# STM32H7x5 register map
File version: 1.1
CPU: CM7 r0p0, little endian, no MPU, no FPU, 3 interrupt priority bits
Registers are 32-bit, read-write, reset 0x0 unless marked. A register's access mark holds for its fields unless they carry their own. Offsets are from the block's base; [hi:lo] are bit positions; {n}, {i} and the like mark numbered series; 'fields as' and 'values as' point back to an identical list.

## FMC
Base 0x52004000
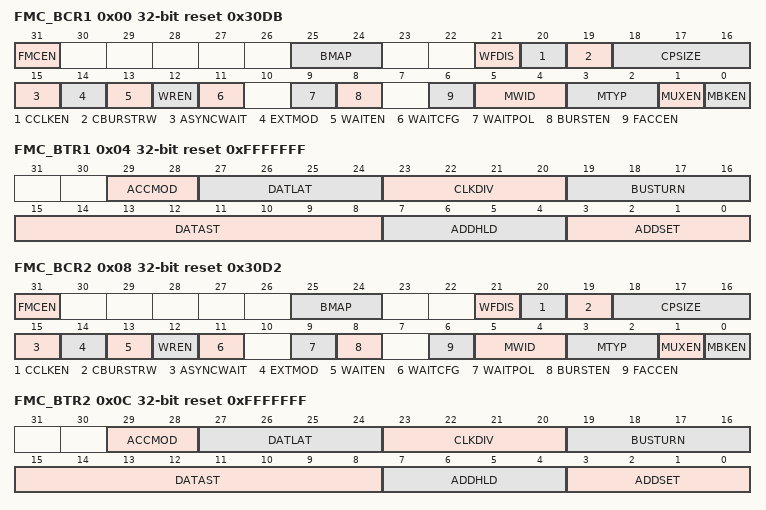
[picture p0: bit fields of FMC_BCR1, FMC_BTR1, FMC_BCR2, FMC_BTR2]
0x00 FMC_BCR1 reset 0x30DB — This register contains the control information of each memory bank, used for SRAMs, PSRAM and NOR Flash memories.
  [31] FMCEN — FMC controller Enable This bit enables/disables the FMC controller. Note: The FMCEN bit of the FMC_BCR2..4 registers is dont care. It is only enabled through the FMC_BCR1 register.
  [25:24] BMAP — FMC bank mapping These bits allows different to remap SDRAM bank2 or swap the FMC NOR/PSRAM and SDRAM banks.Refer to Table 10 for Note: The BMAP bits of the FMC_BCR2..4 registers are dont care. It is only enabled through the FMC_BCR1 register.
  [21] WFDIS — Write FIFO Disable This bit disables the Write FIFO used by the FMC controller. Note: The WFDIS bit of the FMC_BCR2..4 registers is dont care. It is only enabled through the FMC_BCR1 register.
  [20] CCLKEN — Continuous Clock Enable This bit enables the FMC_CLK clock output to external memory devices. Note: The CCLKEN bit of the FMC_BCR2..4 registers is dont care. It is only enabled through the FMC_BCR1 register. Bank 1 must be configured in synchronous mode to generate the FMC_CLK continuous clock. If CCLKEN bit is set, the FMC_CLK clock ratio is specified by CLKDIV value in the FMC_BTR1 register. CLKDIV in FMC_BWTR1 is dont care. If the synchronous mode is used and CCLKEN bit is set, the synchronous memories connected to other banks than Bank 1 are clocked by the same clock (the CLKDIV value in the FMC_BTR2..4 and FMC_BWTR2..4 registers for other banks has no effect.)
  [19] CBURSTRW — Write burst enable For PSRAM (CRAM) operating in Burst mode, the bit enables synchronous accesses during write operations. The enable bit for synchronous read accesses is the BURSTEN bit in the FMC_BCRx register.
  [18:16] CPSIZE — CRAM Page Size These are used for Cellular RAM 1.5 which does not allow burst access to cross the address boundaries between pages. When these bits are configured, the FMC controller splits automatically the burst access when the memory page size is reached (refer to memory datasheet for page size). Other configuration: reserved.
  [15] ASYNCWAIT — Wait signal during asynchronous transfers This bit enables/disables the FMC to use the wait signal even during an asynchronous protocol.
  [14] EXTMOD — Extended mode enable. This bit enables the FMC to program the write timings for asynchronous accesses inside the FMC_BWTR register, thus resulting in different timings for read and write operations. Note: When the extended mode is disabled, the FMC can operate in Mode1 or Mode2 as follows: ** Mode 1 is the default mode when the SRAM/PSRAM memory type is selected (MTYP =0x0 or 0x01) ** Mode 2 is the default mode when the NOR memory type is selected (MTYP = 0x10).
  [13] WAITEN — Wait enable bit This bit enables/disables wait-state insertion via the NWAIT signal when accessing the memory in synchronous mode.
  [12] WREN — Write enable bit This bit indicates whether write operations are enabled/disabled in the bank by the FMC:
  [11] WAITCFG — Wait timing configuration The NWAIT signal indicates whether the data from the memory are valid or if a wait state must be inserted when accessing the memory in synchronous mode. This configuration bit determines if NWAIT is asserted by the memory one clock cycle before the wait state or during the wait state:
  [9] WAITPOL — Wait signal polarity bit This bit defines the polarity of the wait signal from memory used for either in synchronous or asynchronous mode:
  [8] BURSTEN — Burst enable bit This bit enables/disables synchronous accesses during read operations. It is valid only for synchronous memories operating in Burst mode:
  [6] FACCEN — Flash access enable This bit enables NOR Flash memory access operations.
  [5:4] MWID — Memory data bus width Defines the external memory device width, valid for all type of memories.
  [3:2] MTYP — Memory type These bits define the type of external memory attached to the corresponding memory bank:
  [1] MUXEN — Address/data multiplexing enable bit When this bit is set, the address and data values are multiplexed on the data bus, valid only with NOR and PSRAM memories:
  [0] MBKEN — Memory bank enable bit This bit enables the memory bank. After reset Bank1 is enabled, all others are disabled. Accessing a disabled bank causes an ERROR on AXI bus.
0x04 FMC_BTR1 reset 0xFFFFFFF — This register contains the control information of each memory bank, used for SRAMs, PSRAM and NOR Flash memories.If the EXTMOD bit is set in the FMC_BCRx register, then this register is partitioned for write and read access, that is, 2 registers are available: one to configure read accesses (this register) and one to configure write accesses (FMC_BWTRx registers).
  [29:28] ACCMOD — Access mode These bits specify the asynchronous access modes as shown in the timing diagrams. They are taken into account only when the EXTMOD bit in the FMC_BCRx register is 1.
  [27:24] DATLAT — Data latency for synchronous memory For synchronous access with read write burst mode enabled these bits define the number of memory clock cycles
  [23:20] CLKDIV — Clock divide ratio (for FMC_CLK signal) These bits define the period of FMC_CLK clock output signal, expressed in number of KCK_FMC cycles: In asynchronous NOR Flash, SRAM or PSRAM accesses, this value is dont care. Note: Refer to Section20.6.5: Synchronous transactions for FMC_CLK divider ratio formula)
  [19:16] BUSTURN — Bus turnaround phase duration These bits are written by software to add a delay at the end of a write-to-read or read-to write transaction. The programmed bus turnaround delay is inserted between an asynchronous read (in muxed or mode D) or write transaction and any other asynchronous /synchronous read/write from/to a static bank. If a read operation is performed, the bank can be the same or a different one, whereas it must be different in case of write operation to the bank, except in muxed mode or mode D. In some cases, whatever the programmed BUSTRUN values, the bus turnaround delay is fixed as follows: The bus turnaround delay is not inserted between two consecutive asynchronous write transfers to the same static memory bank except in muxed mode and mode D. There is a bus turnaround delay of 1 FMC clock cycle between: Two consecutive asynchronous read transfers to the same static memory bank except for modes muxed and D. An asynchronous read to an asynchronous or synchronous write to any static bank or dynamic bank except in modes muxed and D mode. There is a bus turnaround delay of 2 FMC clock cycle between: Two consecutive synchronous write operations (in Burst or Single mode) to the same bank. A synchronous write (burst or single) access and an asynchronous write or read transfer to or from static memory bank (the bank can be the same or a different one in case of a read operation. Two consecutive synchronous read operations (in Burst or Single mode) followed by any synchronous/asynchronous read or write from/to another static memory bank. There is a bus turnaround delay of 3 FMC clock cycle between: Two consecutive synchronous write operations (in Burst or Single mode) to different static banks. A synchronous write access (in Burst or Single mode) and a synchronous read from the same or a different bank. The bus turnaround delay allows to match the minimum time between consecutive transactions (tEHEL from NEx high to NEx low) and the maximum time required by the memory to free the data bus after a read access (tEHQZ): (BUSTRUN + 1) KCK_FMC period ≥ tEHELmin and (BUSTRUN + 2)KCK_FMC period ≥ tEHQZmax if EXTMOD = 0 (BUSTRUN + 2)KCK_FMC period ≥ max (tEHELmin, tEHQZmax) if EXTMOD = 126. ...
  [15:8] DATAST — Data-phase duration These bits are written by software to define the duration of the data phase (refer to Figure81 to Figure93), used in asynchronous accesses: For each memory type and access mode data-phase duration, please refer to the respective figure (Figure81 to Figure93). Example: Mode1, write access, DATAST=1: Data-phase duration= DATAST+1 = 2 KCK_FMC clock cycles. Note: In synchronous accesses, this value is dont care.
  [7:4] ADDHLD — Address-hold phase duration These bits are written by software to define the duration of the address hold phase (refer to Figure81 to Figure93), used in mode D or multiplexed accesses: For each access mode address-hold phase duration, please refer to the respective figure (Figure81 to Figure93). Note: In synchronous accesses, this value is not used, the address hold phase is always 1 memory clock period duration.
  [3:0] ADDSET — Address setup phase duration These bits are written by software to define the duration of the address setup phase (refer to Figure81 to Figure93), used in SRAMs, ROMs and asynchronous NOR Flash: For each access mode address setup phase duration, please refer to the respective figure (refer to Figure81 to Figure93). Note: In synchronous accesses, this value is dont care. In Muxed mode or Mode D, the minimum value for ADDSET is 1.
0x08 FMC_BCR2 reset 0x30D2 — This register contains the control information of each memory bank, used for SRAMs, PSRAM and NOR Flash memories.
  fields as FMC_BCR1
0x0C FMC_BTR2 reset 0xFFFFFFF — This register contains the control information of each memory bank, used for SRAMs, PSRAM and NOR Flash memories.If the EXTMOD bit is set in the FMC_BCRx register, then this register is partitioned for write and read access, that is, 2 registers are available: one to configure read accesses (this register) and one to configure write accesses (FMC_BWTRx registers).
  [29:28] ACCMOD — Access mode These bits specify the asynchronous access modes as shown in the timing diagrams. They are taken into account only when the EXTMOD bit in the FMC_BCRx register is 1.
  [27:24] DATLAT — Data latency for synchronous memory For synchronous access with read write burst mode enabled these bits define the number of memory clock cycles
  [23:20] CLKDIV — Clock divide ratio (for FMC_CLK signal) These bits define the period of FMC_CLK clock output signal, expressed in number of KCK_FMC cycles: In asynchronous NOR Flash, SRAM or PSRAM accesses, this value is dont care. Note: Refer to Section20.6.5: Synchronous transactions for FMC_CLK divider ratio formula)
  [19:16] BUSTURN — Bus turnaround phase duration These bits are written by software to add a delay at the end of a write-to-read or read-to write transaction. The programmed bus turnaround delay is inserted between an asynchronous read (in muxed or mode D) or write transaction and any other asynchronous /synchronous read/write from/to a static bank. If a read operation is performed, the bank can be the same or a different one, whereas it must be different in case of write operation to the bank, except in muxed mode or mode D. In some cases, whatever the programmed BUSTRUN values, the bus turnaround delay is fixed as follows: The bus turnaround delay is not inserted between two consecutive asynchronous write transfers to the same static memory bank except in muxed mode and mode D. There is a bus turnaround delay of 1 FMC clock cycle between: Two consecutive asynchronous read transfers to the same static memory bank except for modes muxed and D. An asynchronous read to an asynchronous or synchronous write to any static bank or dynamic bank except in modes muxed and D mode. There is a bus turnaround delay of 2 FMC clock cycle between: Two consecutive synchronous write operations (in Burst or Single mode) to the same bank. A synchronous write (burst or single) access and an asynchronous write or read transfer to or from static memory bank (the bank can be the same or a different one in case of a read operation. Two consecutive synchronous read operations (in Burst or Single mode) followed by any synchronous/asynchronous read or write from/to another static memory bank. There is a bus turnaround delay of 3 FMC clock cycle between: Two consecutive synchronous write operations (in Burst or Single mode) to different static banks. A synchronous write access (in Burst or Single mode) and a synchronous read from the same or a different bank. The bus turnaround delay allows to match the minimum time between consecutive transactions (tEHEL from NEx high to NEx low) and the maximum time required by the memory to free the data bus after a read access (tEHQZ): (BUSTRUN + 1) KCK_FMC period ≥ tEHELmin and (BUSTRUN + 2)KCK_FMC period ≥ tEHQZmax if EXTMOD = 0 (BUSTRUN + 2)KCK_FMC period ≥ max (tEHELmin, tEHQZmax) if EXTMOD = 1. ...
  [15:8] DATAST — Data-phase duration These bits are written by software to define the duration of the data phase (refer to Figure81 to Figure93), used in asynchronous accesses: For each memory type and access mode data-phase duration, please refer to the respective figure (Figure81 to Figure93). Example: Mode1, write access, DATAST=1: Data-phase duration= DATAST+1 = 2 KCK_FMC clock cycles. Note: In synchronous accesses, this value is dont care.
  [7:4] ADDHLD — Address-hold phase duration These bits are written by software to define the duration of the address hold phase (refer to Figure81 to Figure93), used in mode D or multiplexed accesses: For each access mode address-hold phase duration, please refer to the respective figure (Figure81 to Figure93). Note: In synchronous accesses, this value is not used, the address hold phase is always 1 memory clock period duration.
  [3:0] ADDSET — Address setup phase duration These bits are written by software to define the duration of the address setup phase (refer to Figure81 to Figure93), used in SRAMs, ROMs and asynchronous NOR Flash: For each access mode address setup phase duration, please refer to the respective figure (refer to Figure81 to Figure93). Note: In synchronous accesses, this value is dont care. In Muxed mode or Mode D, the minimum value for ADDSET is 1.
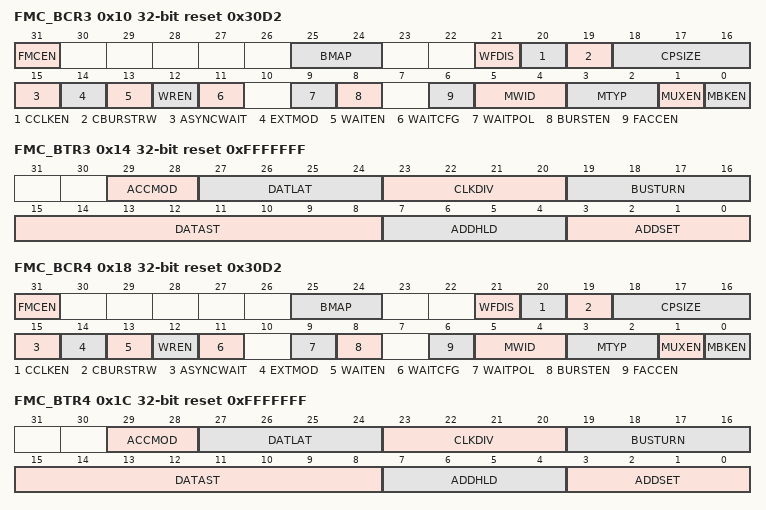
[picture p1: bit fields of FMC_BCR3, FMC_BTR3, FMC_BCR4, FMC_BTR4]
0x10 FMC_BCR3 reset 0x30D2 — This register contains the control information of each memory bank, used for SRAMs, PSRAM and NOR Flash memories.
  fields as FMC_BCR1
0x14 FMC_BTR3 reset 0xFFFFFFF — This register contains the control information of each memory bank, used for SRAMs, PSRAM and NOR Flash memories.If the EXTMOD bit is set in the FMC_BCRx register, then this register is partitioned for write and read access, that is, 2 registers are available: one to configure read accesses (this register) and one to configure write accesses (FMC_BWTRx registers).
  [29:28] ACCMOD — Access mode These bits specify the asynchronous access modes as shown in the timing diagrams. They are taken into account only when the EXTMOD bit in the FMC_BCRx register is 1.
  [27:24] DATLAT — Data latency for synchronous memory For synchronous access with read write burst mode enabled these bits define the number of memory clock cycles
  [23:20] CLKDIV — Clock divide ratio (for FMC_CLK signal) These bits define the period of FMC_CLK clock output signal, expressed in number of KCK_FMC cycles: In asynchronous NOR Flash, SRAM or PSRAM accesses, this value is dont care. Note: Refer to Section20.6.5: Synchronous transactions for FMC_CLK divider ratio formula)
  [19:16] BUSTURN — Bus turnaround phase duration These bits are written by software to add a delay at the end of a write-to-read or read-to write transaction. The programmed bus turnaround delay is inserted between an asynchronous read (in muxed or mode D) or write transaction and any other asynchronous /synchronous read/write from/to a static bank. If a read operation is performed, the bank can be the same or a different one, whereas it must be different in case of write operation to the bank, except in muxed mode or mode D. In some cases, whatever the programmed BUSTRUN values, the bus turnaround delay is fixed as follows: The bus turnaround delay is not inserted between two consecutive asynchronous write transfers to the same static memory bank except in muxed mode and mode D. There is a bus turnaround delay of 1 FMC clock cycle between: Two consecutive asynchronous read transfers to the same static memory bank except for modes muxed and D. An asynchronous read to an asynchronous or synchronous write to any static bank or dynamic bank except in modes muxed and D mode. There is a bus turnaround delay of 2 FMC clock cycle between: Two consecutive synchronous write operations (in Burst or Single mode) to the same bank. A synchronous write (burst or single) access and an asynchronous write or read transfer to or from static memory bank (the bank can be the same or a different one in case of a read operation. Two consecutive synchronous read operations (in Burst or Single mode) followed by any synchronous/asynchronous read or write from/to another static memory bank. There is a bus turnaround delay of 3 FMC clock cycle between: Two consecutive synchronous write operations (in Burst or Single mode) to different static banks. A synchronous write access (in Burst or Single mode) and a synchronous read from the same or a different bank. The bus turnaround delay allows to match the minimum time between consecutive transactions (tEHEL from NEx high to NEx low) and the maximum time required by the memory to free the data bus after a read access (tEHQZ): (BUSTRUN + 1) KCK_FMC period ≥ tEHELmin and (BUSTRUN + 2)KCK_FMC period ≥ tEHQZmax if EXTMOD = 0 (BUSTRUN + 2)KCK_FMC period ≥ max (tEHELmin, tEHQZmax) if EXTMOD =1. ...
  [15:8] DATAST — Data-phase duration These bits are written by software to define the duration of the data phase (refer to Figure81 to Figure93), used in asynchronous accesses: For each memory type and access mode data-phase duration, please refer to the respective figure (Figure81 to Figure93). Example: Mode1, write access, DATAST=1: Data-phase duration= DATAST+1 = 2 KCK_FMC clock cycles. Note: In synchronous accesses, this value is dont care.
  [7:4] ADDHLD — Address-hold phase duration These bits are written by software to define the duration of the address hold phase (refer to Figure81 to Figure93), used in mode D or multiplexed accesses: For each access mode address-hold phase duration, please refer to the respective figure (Figure81 to Figure93). Note: In synchronous accesses, this value is not used, the address hold phase is always 1 memory clock period duration.
  [3:0] ADDSET — Address setup phase duration These bits are written by software to define the duration of the address setup phase (refer to Figure81 to Figure93), used in SRAMs, ROMs and asynchronous NOR Flash: For each access mode address setup phase duration, please refer to the respective figure (refer to Figure81 to Figure93). Note: In synchronous accesses, this value is dont care. In Muxed mode or Mode D, the minimum value for ADDSET is 1.
0x18 FMC_BCR4 reset 0x30D2 — This register contains the control information of each memory bank, used for SRAMs, PSRAM and NOR Flash memories.
  fields as FMC_BCR1
0x1C FMC_BTR4 reset 0xFFFFFFF — This register contains the control information of each memory bank, used for SRAMs, PSRAM and NOR Flash memories.If the EXTMOD bit is set in the FMC_BCRx register, then this register is partitioned for write and read access, that is, 2 registers are available: one to configure read accesses (this register) and one to configure write accesses (FMC_BWTRx registers).
  fields as FMC_BTR3
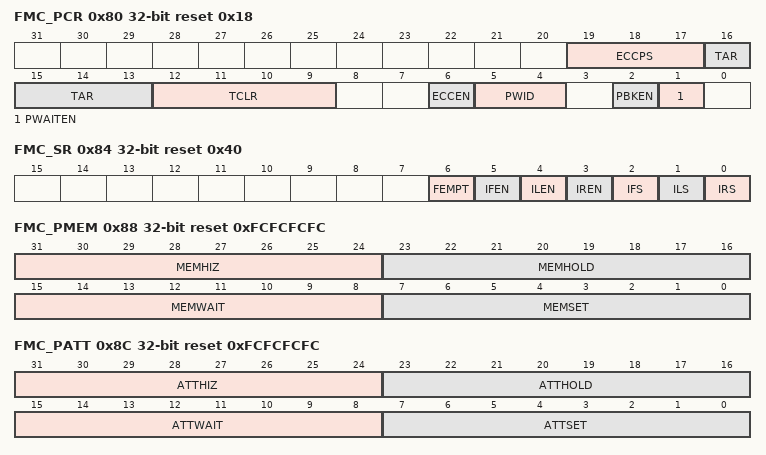
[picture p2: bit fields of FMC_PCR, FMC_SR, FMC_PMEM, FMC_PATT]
0x80 FMC_PCR reset 0x18 — NAND Flash control registers
  [19:17] ECCPS — ECC page size. These bits define the page size for the extended ECC:
  [16:13] TAR — ALE to RE delay. These bits set time from ALE low to RE low in number of KCK_FMC clock cycles. Time is: t_ar = (TAR + SET + 2) TKCK_FMC where TKCK_FMC is the FMC clock period Note: Set is MEMSET or ATTSET according to the addressed space.
  [12:9] TCLR — CLE to RE delay. These bits set time from CLE low to RE low in number of KCK_FMC clock cycles. The time is give by the following formula: t_clr = (TCLR + SET + 2) TKCK_FMC where TKCK_FMC is the KCK_FMC clock period Note: Set is MEMSET or ATTSET according to the addressed space.
  [6] ECCEN — ECC computation logic enable bit
  [5:4] PWID — Data bus width. These bits define the external memory device width.
  [2] PBKEN — NAND Flash memory bank enable bit. This bit enables the memory bank. Accessing a disabled memory bank causes an ERROR on AXI bus
  [1] PWAITEN — Wait feature enable bit. This bit enables the Wait feature for the NAND Flash memory bank:
0x84 FMC_SR access per field reset 0x40 — This register contains information about the FIFO status and interrupt. The FMC features a FIFO that is used when writing to memories to transfer up to 16 words of data.This is used to quickly write to the FIFO and free the AXI bus for transactions to peripherals other than the FMC, while the FMC is draining its FIFO into the memory. One of these register bits indicates the status of the FIFO, for ECC purposes.The ECC is calculated while the data are written to the memory. To read the correct ECC, the software must consequently wait until the FIFO is empty.
  [6] FEMPT ro — FIFO empty. Read-only bit that provides the status of the FIFO
  [5] IFEN rw — Interrupt falling edge detection enable bit
  [4] ILEN rw — Interrupt high-level detection enable bit
  [3] IREN rw — Interrupt rising edge detection enable bit
  [2] IFS rw — Interrupt falling edge status The flag is set by hardware and reset by software. Note: If this bit is written by software to 1 it will be set.
  [1] ILS rw — Interrupt high-level status The flag is set by hardware and reset by software.
  [0] IRS rw — Interrupt rising edge status The flag is set by hardware and reset by software. Note: If this bit is written by software to 1 it will be set.
0x88 FMC_PMEM reset 0xFCFCFCFC — The FMC_PMEM read/write register contains the timing information for NAND Flash memory bank. This information is used to access either the common memory space of the NAND Flash for command, address write access and data read/write access.
  [31:24] MEMHIZ — Common memory x data bus Hi-Z time These bits define the number of KCK_FMC clock cycles during which the data bus is kept Hi-Z after the start of a NAND Flash write access to common memory space. This is only valid for write transactions:
  [23:16] MEMHOLD — Common memory hold time These bits define the number of KCK_FMC clock cycles for write accesses and KCK_FMC+1 clock cycles for read accesses during which the address is held (and data for write accesses) after the command is de-asserted (NWE, NOE), for NAND Flash read or write access to common memory space:
  [15:8] MEMWAIT — Common memory wait time These bits define the minimum number of KCK_FMC (+1) clock cycles to assert the command (NWE, NOE), for NAND Flash read or write access to common memory space. The duration of command assertion is extended if the wait signal (NWAIT) is active (low) at the end of the programmed value of KCK_FMC:
  [7:0] MEMSET — Common memory x setup time These bits define the number of KCK_FMC (+1) clock cycles to set up the address before the command assertion (NWE, NOE), for NAND Flash read or write access to common memory space:
0x8C FMC_PATT reset 0xFCFCFCFC — The FMC_PATT read/write register contains the timing information for NAND Flash memory bank. It is used for 8-bit accesses to the attribute memory space of the NAND Flash for the last address write access if the timing must differ from that of previous accesses (for Ready/Busy management, refer to Section20.8.5: NAND Flash prewait feature).
  [31:24] ATTHIZ — Attribute memory data bus Hi-Z time These bits define the number of KCK_FMC clock cycles during which the data bus is kept in Hi-Z after the start of a NAND Flash write access to attribute memory space on socket. Only valid for writ transaction:
  [23:16] ATTHOLD — Attribute memory hold time These bits define the number of KCK_FMC clock cycles during which the address is held (and data for write access) after the command de-assertion (NWE, NOE), for NAND Flash read or write access to attribute memory space:
  [15:8] ATTWAIT — Attribute memory wait time These bits define the minimum number of x KCK_FMC (+1) clock cycles to assert the command (NWE, NOE), for NAND Flash read or write access to attribute memory space. The duration for command assertion is extended if the wait signal (NWAIT) is active (low) at the end of the programmed value of KCK_FMC:
  [7:0] ATTSET — Attribute memory setup time These bits define the number of KCK_FMC (+1) clock cycles to set up address before the command assertion (NWE, NOE), for NAND Flash read or write access to attribute memory space:
0x94 FMC_ECCR ro — This register contain the current error correction code value computed by the ECC computation modules of the FMC NAND controller. When the CPU reads/writes the data from a NAND Flash memory page at the correct address (refer to Section20.8.6: Computation of the error correction code (ECC) in NAND Flash memory), the data read/written from/to the NAND Flash memory are processed automatically by the ECC computation module. When X bytes have been read (according to the ECCPS field in the FMC_PCR registers), the CPU must read the computed ECC value from the FMC_ECC registers. It then verifies if these computed parity data are the same as the parity value recorded in the spare area, to determine whether a page is valid, and, to correct it otherwise. The FMC_ECCR register should be cleared after being read by setting the ECCEN bit to 0. To compute a new data block, the ECCEN bit must be set to 1.
  [31:0] ECC — ECC result This field contains the value computed by the ECC computation logic. Table167 describes the contents of these bit fields.
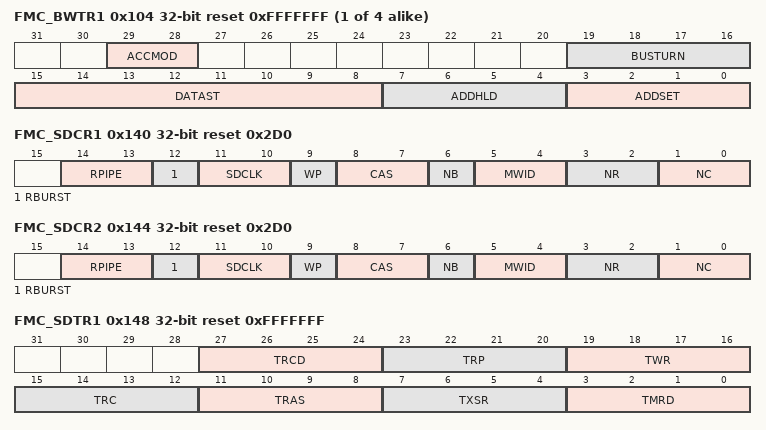
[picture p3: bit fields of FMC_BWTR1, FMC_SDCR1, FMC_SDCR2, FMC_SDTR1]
{0xFC+8i} FMC_BWTR{i} reset 0xFFFFFFF (i=1..4) — This register contains the control information of each memory bank. It is used for SRAMs, PSRAMs and NOR Flash memories. When the EXTMOD bit is set in the FMC_BCRx register, then this register is active for write access.
  [29:28] ACCMOD — Access mode. These bits specify the asynchronous access modes as shown in the next timing diagrams.These bits are taken into account only when the EXTMOD bit in the FMC_BCRx register is 1.
  [19:16] BUSTURN — Bus turnaround phase duration These bits are written by software to add a delay at the end of a write transaction to match the minimum time between consecutive transactions (tEHEL from ENx high to ENx low): (BUSTRUN + 1) KCK_FMC period ≥ tEHELmin. The programmed bus turnaround delay is inserted between a an asynchronous write transfer and any other asynchronous /synchronous read or write transfer to or from a static bank. If a read operation is performed, the bank can be the same or a different one, whereas it must be different in case of write operation to the bank, except in muxed mode or mode D. In some cases, whatever the programmed BUSTRUN values, the bus turnaround delay is fixed as follows: The bus turnaround delay is not inserted between two consecutive asynchronous write transfers to the same static memory bank except for muxed mode and mode D. There is a bus turnaround delay of 2 FMC clock cycle between: Two consecutive synchronous write operations (in Burst or Single mode) to the same bank A synchronous write transfer ((in Burst or Single mode) and an asynchronous write or read transfer to or from static memory bank. There is a bus turnaround delay of 3 FMC clock cycle between: Two consecutive synchronous write operations (in Burst or Single mode) to different static banks. A synchronous write transfer (in Burst or Single mode) and a synchronous read from the same or a different bank. ...
  [15:8] DATAST — Data-phase duration. These bits are written by software to define the duration of the data phase (refer to Figure81 to Figure93), used in asynchronous SRAM, PSRAM and NOR Flash memory accesses:
  [7:4] ADDHLD — Address-hold phase duration. These bits are written by software to define the duration of the address hold phase (refer to Figure81 to Figure93), used in asynchronous multiplexed accesses: ... Note: In synchronous NOR Flash accesses, this value is not used, the address hold phase is always 1 Flash clock period duration.
  [3:0] ADDSET — Address setup phase duration. These bits are written by software to define the duration of the address setup phase in KCK_FMC cycles (refer to Figure81 to Figure93), used in asynchronous accesses: ... Note: In synchronous accesses, this value is not used, the address setup phase is always 1 Flash clock period duration. In muxed mode, the minimum ADDSET value is 1.
0x140 FMC_SDCR1 reset 0x2D0 — This register contains the control parameters for each SDRAM memory bank
  [14:13] RPIPE — Read pipe These bits define the delay, in KCK_FMC clock cycles, for reading data after CAS latency. Note: The corresponding bits in the FMC_SDCR2 register is read only.
  [12] RBURST — Burst read This bit enables burst read mode. The SDRAM controller anticipates the next read commands during the CAS latency and stores data in the Read FIFO. Note: The corresponding bit in the FMC_SDCR2 register is read only.
  [11:10] SDCLK — SDRAM clock configuration These bits define the SDRAM clock period for both SDRAM banks and allow disabling the clock before changing the frequency. In this case the SDRAM must be re-initialized. Note: The corresponding bits in the FMC_SDCR2 register is read only.
  [9] WP — Write protection This bit enables write mode access to the SDRAM bank.
  [8:7] CAS — CAS Latency This bits sets the SDRAM CAS latency in number of memory clock cycles
  [6] NB — Number of internal banks This bit sets the number of internal banks.
  [5:4] MWID — Memory data bus width. These bits define the memory device width.
  [3:2] NR — Number of row address bits These bits define the number of bits of a row address.
  [1:0] NC — Number of column address bits These bits define the number of bits of a column address.
0x144 FMC_SDCR2 reset 0x2D0 — This register contains the control parameters for each SDRAM memory bank
  fields as FMC_SDCR1
0x148 FMC_SDTR1 reset 0xFFFFFFF — This register contains the timing parameters of each SDRAM bank
  [27:24] TRCD — Row to column delay These bits define the delay between the Activate command and a Read/Write command in number of memory clock cycles. ....
  [23:20] TRP — Row precharge delay These bits define the delay between a Precharge command and another command in number of memory clock cycles. The TRP timing is only configured in the FMC_SDTR1 register. If two SDRAM devices are used, the TRP must be programmed with the timing of the slowest device. .... Note: The corresponding bits in the FMC_SDTR2 register are dont care.
  [19:16] TWR — Recovery delay These bits define the delay between a Write and a Precharge command in number of memory clock cycles. .... Note: TWR must be programmed to match the write recovery time (tWR) defined in the SDRAM datasheet, and to guarantee that: TWR ≥ TRAS - TRCD and TWR ≥TRC - TRCD - TRP Example: TRAS= 4 cycles, TRCD= 2 cycles. So, TWR >= 2 cycles. TWR must be programmed to 0x1. If two SDRAM devices are used, the FMC_SDTR1 and FMC_SDTR2 must be programmed with the same TWR timing corresponding to the slowest SDRAM device.
  [15:12] TRC — Row cycle delay These bits define the delay between the Refresh command and the Activate command, as well as the delay between two consecutive Refresh commands. It is expressed in number of memory clock cycles. The TRC timing is only configured in the FMC_SDTR1 register. If two SDRAM devices are used, the TRC must be programmed with the timings of the slowest device. .... Note: TRC must match the TRC and TRFC (Auto Refresh period) timings defined in the SDRAM device datasheet. Note: The corresponding bits in the FMC_SDTR2 register are dont care.
  [11:8] TRAS — Self refresh time These bits define the minimum Self-refresh period in number of memory clock cycles. ....
  [7:4] TXSR — Exit Self-refresh delay These bits define the delay from releasing the Self-refresh command to issuing the Activate command in number of memory clock cycles. .... Note: If two SDRAM devices are used, the FMC_SDTR1 and FMC_SDTR2 must be programmed with the same TXSR timing corresponding to the slowest SDRAM device.
  [3:0] TMRD — Load Mode Register to Active These bits define the delay between a Load Mode Register command and an Active or Refresh command in number of memory clock cycles. ....
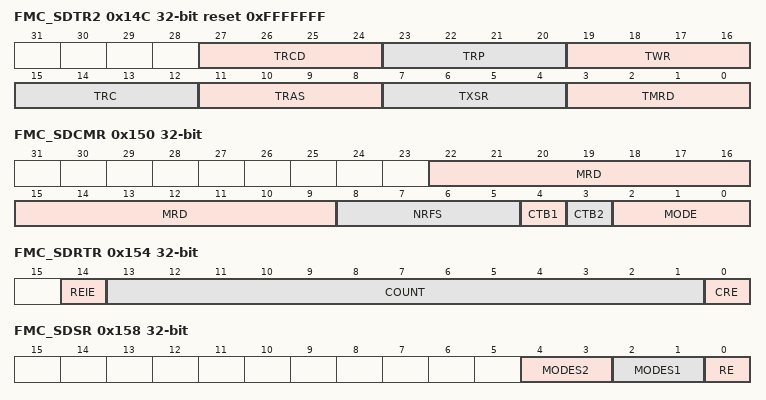
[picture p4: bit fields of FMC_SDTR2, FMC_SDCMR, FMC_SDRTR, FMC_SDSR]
0x14C FMC_SDTR2 reset 0xFFFFFFF — This register contains the timing parameters of each SDRAM bank
  fields as FMC_SDTR1
0x150 FMC_SDCMR — This register contains the command issued when the SDRAM device is accessed. This register is used to initialize the SDRAM device, and to activate the Self-refresh and the Power-down modes. As soon as the MODE field is written, the command will be issued only to one or to both SDRAM banks according to CTB1 and CTB2 command bits. This register is the same for both SDRAM banks.
  [22:9] MRD — Mode Register definition This 14-bit field defines the SDRAM Mode Register content. The Mode Register is programmed using the Load Mode Register command. The MRD[13:0] bits are also used to program the extended mode register for mobile SDRAM.
  [8:5] NRFS — Number of Auto-refresh These bits define the number of consecutive Auto-refresh commands issued when MODE = 011. ....
  [4] CTB1 — Command Target Bank 1 This bit indicates whether the command will be issued to SDRAM Bank 1 or not.
  [3] CTB2 — Command Target Bank 2 This bit indicates whether the command will be issued to SDRAM Bank 2 or not.
  [2:0] MODE — Command mode These bits define the command issued to the SDRAM device. Note: When a command is issued, at least one Command Target Bank bit ( CTB1 or CTB2) must be set otherwise the command will be ignored. Note: If two SDRAM banks are used, the Auto-refresh and PALL command must be issued simultaneously to the two devices with CTB1 and CTB2 bits set otherwise the command will be ignored. Note: If only one SDRAM bank is used and a command is issued with its associated CTB bit set, the other CTB bit of the unused bank must be kept to 0.
0x154 FMC_SDRTR access per field — This register sets the refresh rate in number of SDCLK clock cycles between the refresh cycles by configuring the Refresh Timer Count value.Examplewhere 64 ms is the SDRAM refresh period.The refresh rate must be increased by 20 SDRAM clock cycles (as in the above example) to obtain a safe margin if an internal refresh request occurs when a read request has been accepted. It corresponds to a COUNT value of 0000111000000 (448). This 13-bit field is loaded into a timer which is decremented using the SDRAM clock. This timer generates a refresh pulse when zero is reached. The COUNT value must be set at least to 41 SDRAM clock cycles.As soon as the FMC_SDRTR register is programmed, the timer starts counting. If the value programmed in the register is 0, no refresh is carried out. This register must not be reprogrammed after the initialization procedure to avoid modifying the refresh rate.Each time a refresh pulse is generated, this 13-bit COUNT field is reloaded into the counter.If a memory access is in progress, the Auto-refresh request is delayed. However, if the memory access and Auto-refresh requests are generated simultaneously, the Auto-refresh takes precedence. If the memory access occurs during a refresh operation, the request is buffered to be processed when the refresh is complete.This register is common to SDRAM bank 1 and bank 2.
  [14] REIE rw — RES Interrupt Enable
  [13:1] COUNT rw — Refresh Timer Count This 13-bit field defines the refresh rate of the SDRAM device. It is expressed in number of memory clock cycles. It must be set at least to 41 SDRAM clock cycles (0x29). Refresh rate = (COUNT + 1) x SDRAM frequency clock COUNT = (SDRAM refresh period / Number of rows) - 20
  [0] CRE wo — Clear Refresh error flag This bit is used to clear the Refresh Error Flag (RE) in the Status Register.
0x158 FMC_SDSR ro — SDRAM Status register
  [4:3] MODES2 — Status Mode for Bank 2 These bits define the Status Mode of SDRAM Bank 2.
  [2:1] MODES1 — Status Mode for Bank 1 These bits define the Status Mode of SDRAM Bank 1.
  [0] RE — Refresh error flag An interrupt is generated if REIE = 1 and RE = 1
